AUTOSAR XML (schema 00050)
package /ARRoot
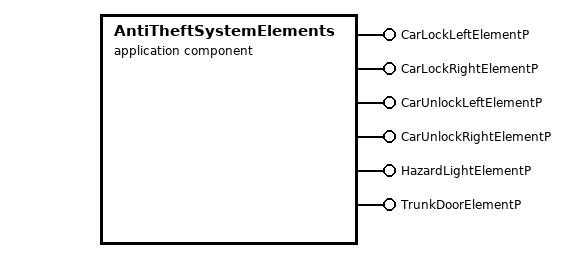
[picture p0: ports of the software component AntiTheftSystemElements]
  application sw component type AntiTheftSystemElements
    6 x provide port:
      CarLockLeftElementP
      CarLockRightElementP
      CarUnlockLeftElementP
      CarUnlockRightElementP
      HazardLightElementP
      TrunkDoorElementP
    behavior AntiTheftSystemElementsIB
      6 x runnable:
        CarLockLeftRunnable: synchronous-server-call-point
        CarLockRightRunnable: synchronous-server-call-point=CarLockElementRight.DoorLockT
        CarUnLockLeftRunnable: synchronous-server-call-point=CarUnLockElementLeft.DoorLockT
        CarUnlockRightRunnable: synchronous-server-call-point=CarUnlockElementRight.DoorLockT
        HazardLightRunnable: synchronous-server-call-point=HazardLightElementR.HazardLightT
        TrunkDoorRunnable: synchronous-server-call-point=TrunkDoorElementR.TrunkdoorT
  sensor actuator sw component type DoorLock/UnlockLedDisplay
  client server interface DoorLockSensor
    operation DoorLockT
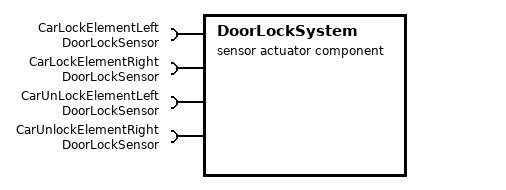
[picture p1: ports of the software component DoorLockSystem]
  sensor actuator sw component type DoorLockSystem
    4 x require port, all with required-interface=DoorLockSensor:
      CarLockElementLeft
      CarLockElementRight
      CarUnLockElementLeft
      CarUnlockElementRight
  sensor actuator sw component type DoorUnlockBeep
  sensor actuator sw component type HazardLedDisplay
    require port HazardLightLEDPort
  client server interface HazardLightSensor
    operation HazardLightT
  sensor actuator sw component type HazardLightSystem
    require port HazardLightElementR: required-interface=HazardLightSensor
  sensor actuator sw component type TrunkDoorLedDisplay
  client server interface TrunkDoorSensor
    operation TrunkdoorT
  sensor actuator sw component type TrunkDoorSystem
    require port TrunkDoorElementR: required-interface=TrunkDoorSensor
